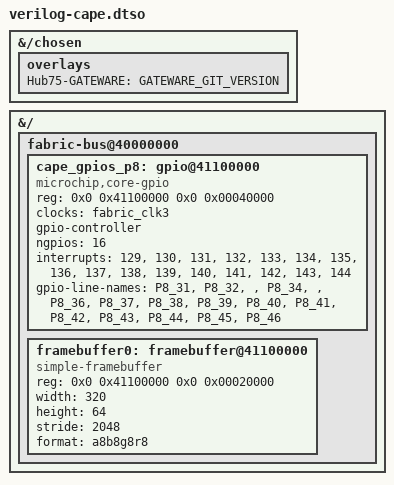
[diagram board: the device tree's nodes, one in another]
// SPDX-License-Identifier: (GPL-2.0 OR MIT)
/* Copyright (c) 2023 Microchip Technology Inc */

/dts-v1/;
/plugin/;

&{/chosen} {
	overlays {
		Hub75-GATEWARE = "GATEWARE_GIT_VERSION";
	};
};

&{/} {

	fabric-bus@40000000 {
		#address-cells = <0x2>;
		#size-cells = <0x2>;
		
		cape_gpios_p8: gpio@41100000 {
			compatible = "microchip,core-gpio";
			reg = <0x0 0x41100000 0x0 0x00040000>;
			clocks = <&fabric_clk3>;
			gpio-controller;
			#gpio-cells = <2>;
			ngpios=<16>;
			status = "okay";
 			interrupts = <129>, <130>, <131>, <132>,
 				     <133>, <134>, <135>, <136>,
 				     <137>, <138>, <139>, <140>,
 				     <141>, <142>, <143>, <144>;

			gpio-line-names = "P8_31", "P8_32", "", "P8_34",
							  "", "P8_36", "P8_37", "P8_38",
							  "P8_39", "P8_40", "P8_41", "P8_42",
							  "P8_43", "P8_44", "P8_45", "P8_46";
		};
		
		framebuffer0: framebuffer@41100000 {
			compatible = "simple-framebuffer";
			reg = <0x0 0x41100000 0x0 0x00020000>;
			width = <320>;
			height = <64>;
			stride = <2048>;
			format = "a8b8g8r8";
			status = "okay";
		};
	};
};

